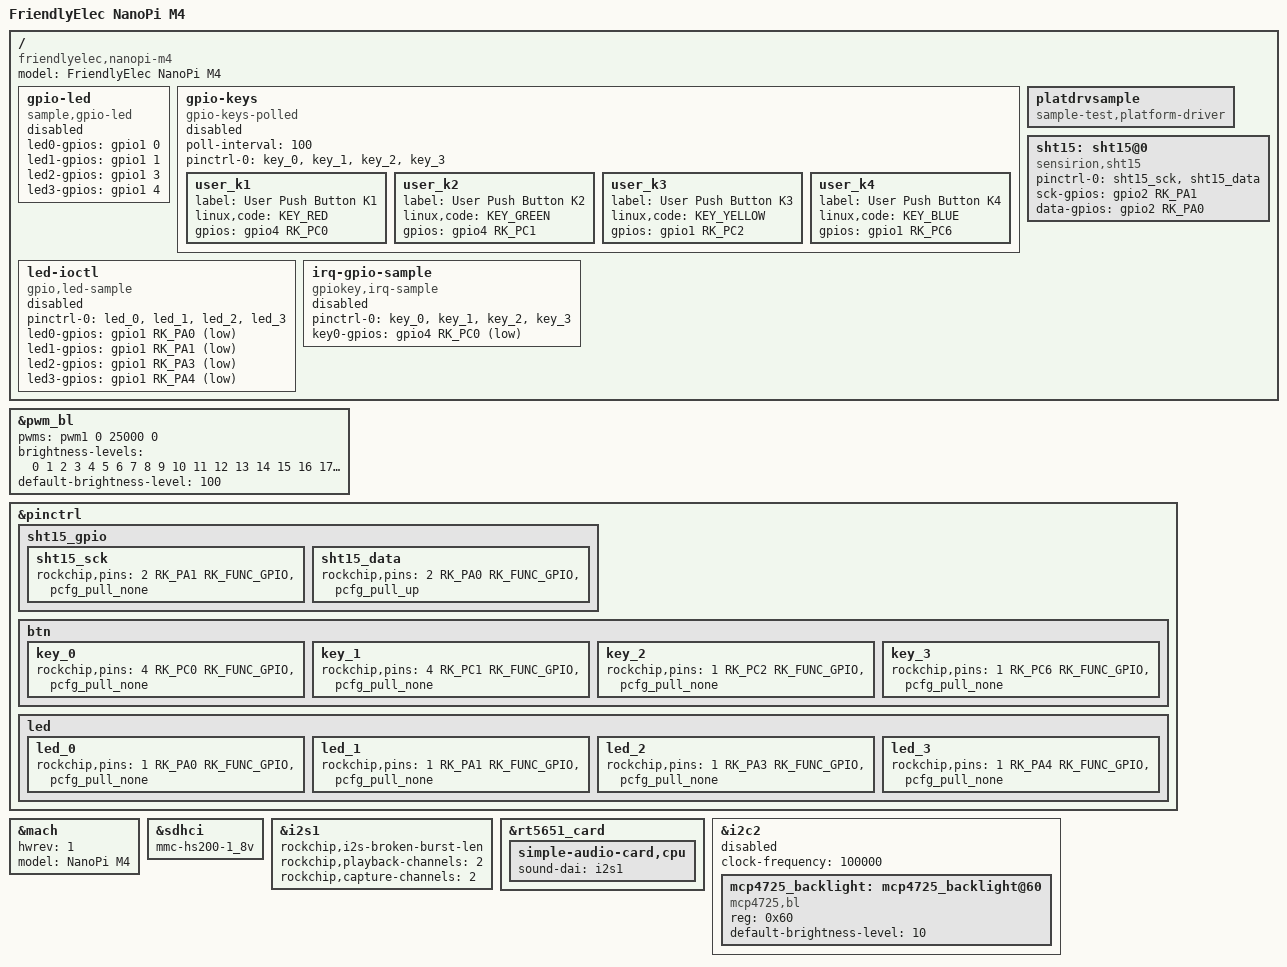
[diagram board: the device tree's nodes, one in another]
/*
 * Copyright (c) 2018 FriendlyElec Computer Tech. Co., Ltd.
 * (http://www.friendlyarm.com)
 *
 * This program is free software; you can redistribute it and/or
 * modify it under the terms of the GNU General Public License
 * as published by the Free Software Foundation; either version 2
 * of the License, or (at your option) any later version.
 *
 * This program is distributed in the hope that it will be useful,
 * but WITHOUT ANY WARRANTY; without even the implied warranty of
 * MERCHANTABILITY or FITNESS FOR A PARTICULAR PURPOSE.  See the
 * GNU General Public License for more details.
 *
 * You should have received a copy of the GNU General Public License
 * along with this program.  If not, see <http://www.gnu.org/licenses/>.
 */

/dts-v1/;
#include "rk3399-nanopi4-common.dtsi"

/ {
	model = "FriendlyElec NanoPi M4";
	compatible = "friendlyelec,nanopi-m4", "rockchip,rk3399";

    gpio-led {
        status = "disabled";
        compatible = "sample,gpio-led";
        led0-gpios = <&gpio1 0 GPIO_ACTIVE_HIGH>;
        led1-gpios = <&gpio1 1 GPIO_ACTIVE_HIGH>;
        led2-gpios = <&gpio1 3 GPIO_ACTIVE_HIGH>;
        led3-gpios = <&gpio1 4 GPIO_ACTIVE_HIGH>;
    };

	gpio-keys {
		compatible = "gpio-keys-polled";
		poll-interval = <100>;
		status = "disabled";

		pinctrl-names = "default";
		pinctrl-0 = <&key_0 &key_1 &key_2 &key_3>;

		user_k1 {
			label = "User Push Button K1";
			linux,code = <KEY_RED>;
			gpios = <&gpio4 RK_PC0 GPIO_ACTIVE_HIGH>;
		};

		user_k2 {
			label = "User Push Button K2";
			linux,code = <KEY_GREEN>;
			gpios = <&gpio4 RK_PC1 GPIO_ACTIVE_HIGH>;
		};

		user_k3 {
			label = "User Push Button K3";
			linux,code = <KEY_YELLOW>;
			gpios = <&gpio1 RK_PC2 GPIO_ACTIVE_HIGH>;
		};

		user_k4 {
			label = "User Push Button K4";
			linux,code = <KEY_BLUE>;
			gpios = <&gpio1 RK_PC6 GPIO_ACTIVE_HIGH>;
		};
	};

    led-ioctl {
        status = "disabled";
        compatible = "gpio,led-sample";
        pinctrl-names = "default";
        pinctrl-0 = <&led_0 &led_1 &led_2 &led_3>;
        led0-gpios = <&gpio1 RK_PA0 GPIO_ACTIVE_LOW>;
        led1-gpios = <&gpio1 RK_PA1 GPIO_ACTIVE_LOW>;
        led2-gpios = <&gpio1 RK_PA3 GPIO_ACTIVE_LOW>;
        led3-gpios = <&gpio1 RK_PA4 GPIO_ACTIVE_LOW>;
    };

    irq-gpio-sample {
        status = "disabled";
        compatible = "gpiokey,irq-sample";
        //compatible = "sample,key-bad";
        pinctrl-names = "default";
        pinctrl-0 = <&key_0 &key_1 &key_2 &key_3>;
        key0-gpios = <&gpio4 RK_PC0 GPIO_ACTIVE_LOW>;
    };

    platdrvsample:platdrvsample {
        status = "okay";
        compatible = "sample-test,platform-driver";
    };

    sht15: sht15@0 {
        status = "okay";
        compatible = "sensirion,sht15";
        pinctrl-names = "default";
        pinctrl-0 = <&sht15_sck &sht15_data>;
        sck-gpios = <&gpio2 RK_PA1 GPIO_ACTIVE_HIGH>;
        data-gpios = <&gpio2 RK_PA0 GPIO_ACTIVE_HIGH>;
    };
};

&pwm_bl {
	status = "okay";
	pwms = <&pwm1 0 25000 0>;

		brightness-levels = <
			  0   1   2   3   4   5   6   7
			  8   9  10  11  12  13  14  15
			 16  17  18  19  20  21  22  23
			 24  25  26  27  28  29  30  31
			 32  33  34  35  36  37  38  39
			 40  41  42  43  44  45  46  47
			 48  49  50  51  52  53  54  55
			 56  57  58  59  60  61  62  63
			 64  65  66  67  68  69  70  71
			 72  73  74  75  76  77  78  79
			 80  81  82  83  84  85  86  87
			 88  89  90  91  92  93  94  95
			 96  97  98  99 100>;
		default-brightness-level = <100>;
};

&pinctrl {
	sht15_gpio {
		sht15_sck: sht15_sck {
			rockchip,pins = <2 RK_PA1 RK_FUNC_GPIO &pcfg_pull_none>;
		};
		sht15_data: sht15_data {
			rockchip,pins = <2 RK_PA0 RK_FUNC_GPIO &pcfg_pull_up>;
		};
	};

	btn {
		key_0: key_0 {
			rockchip,pins = <4 RK_PC0 RK_FUNC_GPIO &pcfg_pull_none>;
		};
		key_1: key_1 {
			rockchip,pins = <4 RK_PC1 RK_FUNC_GPIO &pcfg_pull_none>;
		};
		key_2: key_2 {
			rockchip,pins = <1 RK_PC2 RK_FUNC_GPIO &pcfg_pull_none>;
		};
		key_3: key_3 {
			rockchip,pins = <1 RK_PC6 RK_FUNC_GPIO &pcfg_pull_none>;
		};
	};

   led {
        led_0: led_0 {
            rockchip,pins = <1 RK_PA0 RK_FUNC_GPIO &pcfg_pull_none>;
        };
        led_1: led_1 {
            rockchip,pins = <1 RK_PA1 RK_FUNC_GPIO &pcfg_pull_none>;
        };
        led_2: led_2 {
            rockchip,pins = <1 RK_PA3 RK_FUNC_GPIO &pcfg_pull_none>;
        };
        led_3: led_3 {
            rockchip,pins = <1 RK_PA4 RK_FUNC_GPIO &pcfg_pull_none>;
        };
    };
};

&mach {
	hwrev = <1>;
	model = "NanoPi M4";
};

&sdhci {
	mmc-hs200-1_8v;
	/delete-property/ mmc-hs400-1_8v;
	/delete-property/ mmc-hs400-enhanced-strobe;
};

&i2s1 {
	status = "okay";
	rockchip,i2s-broken-burst-len;
	rockchip,playback-channels = <2>;
	rockchip,capture-channels = <2>;
	#sound-dai-cells = <0>;
};

&rt5651_card {
	/delete-property/ pinctrl-0;
	/delete-property/ simple-audio-card,hp-det-gpio;

	simple-audio-card,cpu {
		sound-dai = <&i2s1>;
	};
};

&i2c2 {
	status = "disabled";
	clock-frequency = <100000>;

	mcp4725_backlight: mcp4725_backlight@60 {
		compatible = "mcp4725,bl";
		reg = <0x60>;
		pinctrl-names = "default";
		default-brightness-level = <10>;
		status = "okay";
	};
};
